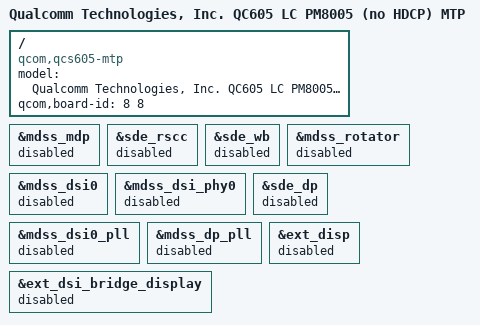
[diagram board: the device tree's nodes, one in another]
/*
 * Copyright (c) 2018, The Linux Foundation. All rights reserved.
 *
 * This program is free software; you can redistribute it and/or modify
 * it under the terms of the GNU General Public License version 2 and
 * only version 2 as published by the Free Software Foundation.
 *
 * This program is distributed in the hope that it will be useful,
 * but WITHOUT ANY WARRANTY; without even the implied warranty of
 * MERCHANTABILITY or FITNESS FOR A PARTICULAR PURPOSE.  See the
 * GNU General Public License for more details.
 */


/dts-v1/;

#include "qcs605-lc.dtsi"
#include "qcs605-lc-mtp.dtsi"
#include "qcs605-lc-audio-overlay.dtsi"

/ {
	model = "Qualcomm Technologies, Inc. QC605 LC PM8005 (no HDCP) MTP";
	compatible = "qcom,qcs605-mtp", "qcom,qcs605", "qcom,mtp";
	qcom,board-id = <8 8>;
};

&mdss_mdp {
		status = "disabled";
};

&sde_rscc {
		status = "disabled";
};

&sde_wb {
		status = "disabled";
};

&mdss_rotator {
		status = "disabled";
};

&mdss_dsi0 {
		status = "disabled";
};

&mdss_dsi_phy0 {
		status = "disabled";
};

&sde_dp {
		status = "disabled";
};

&mdss_dsi0_pll {
		status = "disabled";
};

&mdss_dp_pll {
		status = "disabled";
};

&ext_disp {
		status = "disabled";
};

&ext_dsi_bridge_display {
		status = "disabled";
};
